# CONTROL_MODULE register map
Vendor: Texas Instruments
Registers are 32-bit, access per field, no defined reset value unless marked. A register's access mark holds for its fields unless they carry their own. Offsets are as the file gives them; [hi:lo] are bit positions; lines under a group give offsets from that group; {n}, {i} and the like mark numbered series.

## CONTROL_MODULE (part 2 of 5)
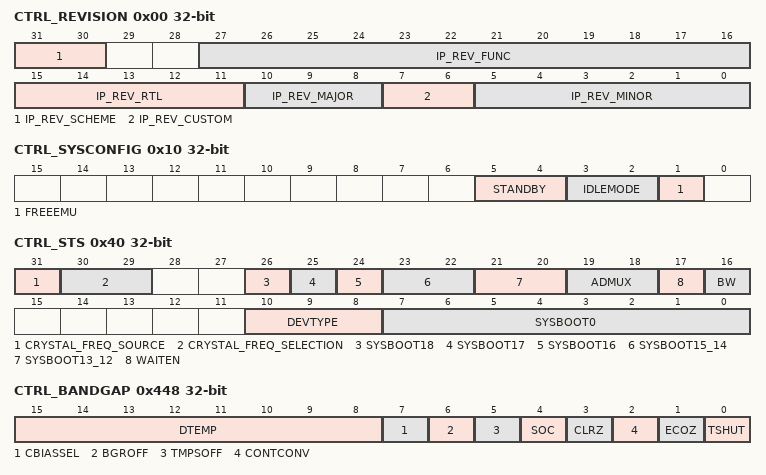
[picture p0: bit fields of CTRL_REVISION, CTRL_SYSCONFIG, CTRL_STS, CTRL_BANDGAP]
0x00 CTRL_REVISION ro
  [31:30] IP_REV_SCHEME — Scheme value
  [27:16] IP_REV_FUNC — Function value
  [15:11] IP_REV_RTL — RTL Version value
  [10:8] IP_REV_MAJOR — Major Revision value
  [7:6] IP_REV_CUSTOM — Custom Version value
  [5:0] IP_REV_MINOR — Minor Revision value
0x04 CTRL_HWINFO ro
  [31:0] IP_HWINFO — IP Module dependent
0x10 CTRL_SYSCONFIG
  [5:4] STANDBY ro — Configure local initiator state management [[br]]00 : Force Standby[[br]] [[br]]01 : No Standby Mode[[br]] [[br]]10 : Smart Standby[[br]] [[br]]11 : Smart Standby wakeup capable[[br]]Reserved in Control Module since it has no local initiator.
  [3:2] IDLEMODE rw — Configure local target state management [[br]]00 : Force Idle[[br]] [[br]]01 : No Idle[[br]] [[br]]10 : Smart Idle[[br]] [[br]]11 : Smart Idle wakeup capable
  [1] FREEEMU ro — Sensitivity to Emulation suspend input. [[br]]0 : Module is sensitive to EMU suspend[[br]] [[br]]1 : Module not sensitive to EMU suspend
0x40 CTRL_STS
  [31] CRYSTAL_FREQ_SOURCE ro — [[br]]0: Use SYSBOOT15_14 (bits 23 to 22) [[br]]1: Use crystal_freq_selection (bits 30 to 29)
  [30:29] CRYSTAL_FREQ_SELECTION ro — This register bitfield is valid only when crystal_freq_source (bit 31) is 1. [[br]]00: selects 19.2MHz[[br]] [[br]]01: selects 24MHz[[br]] [[br]]10: selects 25MHz[[br]] [[br]]11: selects 26MHz
  [26] SYSBOOT18 rw — Reserved for future
  [25] SYSBOOT17 rw — Used by Control Module to determine whether CLKOUT1 pin is selected as default mux mode on device pin xdma_event_intr0. [[br]]1: CLKOUT1 is selected as default mux mode[[br]] [[br]]0: Pinmux Mode0 function is selected as the default mux mode
  [24] SYSBOOT16 rw — Used by boot ROM [[br]]0: QSPI Mux mode 0 or gpmc wait0 Mux mode 0[[br]] [[br]]1: QSPI Mux mode 1 or gpmc wait0 Mux mode 1
  [23:22] SYSBOOT15_14 rw — Used to select crystal clock frequency. [[br]]This register bitfield is valid only when crystal_freq_source (bit 31) is 0. [[br]]00: Selects 19.2MHz[[br]] [[br]]01: Selects 24MHz[[br]] [[br]]10: Selects 25MHz[[br]] [[br]]11: Selects 26MHz
  [21:20] SYSBOOT13_12 rw — Reserved for future use
  [19:18] ADMUX rw — GPMC CS0 Default Address Muxing [[br]]00 : No Addr/Data Muxing[[br]] [[br]]01 : Addr/Addr/Data Muxing[[br]] [[br]]10 : Addr/Data Muxing[[br]] [[br]]11 : Reserved
  [17] WAITEN rw — GPMC CS0 Default Wait Enable [[br]]0 : Ignore WAIT input[[br]] [[br]]1 : Use WAIT input
  [16] BW rw — GPMC CS0 Default Bus Width [[br]]0: 8 bit data bus[[br]]1: 16 bit data bus
  [10:8] DEVTYPE ro — [[br]]000: Reserved[[br]] [[br]]001: Reserved[[br]] [[br]]010: Reserved[[br]] [[br]]011: General Purpose (GP) Device[[br]] [[br]]111: Reserved
  [7:0] SYSBOOT0 rw — SYSBOOT0 (bits 7 to 6): Used by Boot ROM for selecting MII/RMII/RGMII modes(1)[[br]]00b - MII[[br]]01b - RMII[[br]]10b - RGMII with internal delay[[br]]11b - RGMII without internal delay[[br]]SYSBOOT0(bits 5 to 0): ROM Boot Selection
0x1E0 CTRL_MPU_L2
  [16] PIUSEL2SRAM rw — Enables MPUSS L2 Cache as SRAM[[br]] [[br]]0 - Select L2 cache operation[[br]] [[br]]1 - Configure L2 cache as L3 OCMC RAM
0x428 CTRL_CORE_SLDO
  [25:16] VSET rw — Trims VDDAR
0x42C CTRL_MPU_SLDO
  [25:16] VSET rw — Trims VDDAR
0x444 CTRL_CLK32KDIVRATIO
  [0] CLKDIVOPP50_EN rw — [[br]]0 : OPP100 operation use ratio for 24MHz to 32KHz division [[br]]1 : OPP50 operation use ratio for 12MHz to 32KHz division
0x448 CTRL_BANDGAP
  [15:8] DTEMP ro — temperature data from ADC
  [7] CBIASSEL rw — high uses resister divider as reference rather than bandgap. [[br]]Wait 150us after BGROFF=0 then pull it low
  [6] BGROFF rw — high turns off bandgap (OFF mode)
  [5] TMPSOFF rw — high turns off temperature sensor
  [4] SOC rw — high transition starts new ADC conversion cycle
  [3] CLRZ rw — low resets the digital outputs
  [2] CONTCONV rw — high is continuous conversion mode low is single conversion mode
  [1] ECOZ ro — when low DTEMP is valid
  [0] TSHUT ro — goes high during thermal shutdown event (147C)
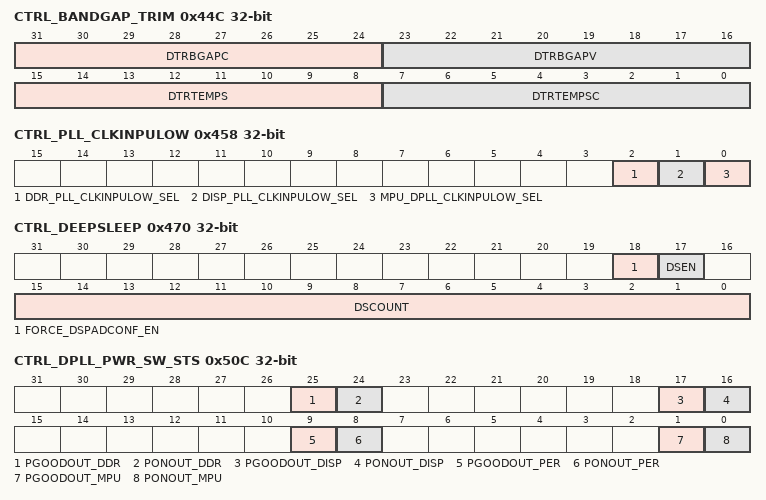
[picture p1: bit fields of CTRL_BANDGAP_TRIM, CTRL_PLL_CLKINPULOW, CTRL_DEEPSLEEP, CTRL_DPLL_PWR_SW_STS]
0x44C CTRL_BANDGAP_TRIM rw
  [31:24] DTRBGAPC — trim the output voltage of bandgap
  [23:16] DTRBGAPV — trim the output voltage of bandgap
  [15:8] DTRTEMPS — trim the temperature sensor
  [7:0] DTRTEMPSC — trim the temperature sensor
0x458 CTRL_PLL_CLKINPULOW
  [2] DDR_PLL_CLKINPULOW_SEL rw — [[br]]0 : Select CORE_CLKOUT_M6 clock as CLKINPULOW [[br]]1 : Select PER_CLKOUT_M2 clock as CLKINPULOW
  [1] DISP_PLL_CLKINPULOW_SEL rw — [[br]]0 : Select CORE_CLKOUT_M6 clock as CLKINPULOW [[br]]1 : Select PER_CLKOUT_M2 clock as CLKINPULOW
  [0] MPU_DPLL_CLKINPULOW_SEL rw — [[br]]0 : Select CORE_CLKOUT_M6 clock as CLKINPULOW [[br]]1 : Select PER_CLKOUT_M2 clock as CLKINPULOW
0x468 CTRL_MOSC
  [0] RESSELECT rw — [[br]]0 : When reselect is low an internal 1megohm resistor is connected between padxi and padxo for oscillator bias. [[br]]1 : When resselect is asserted (high) the internal resistor is disconnected. [[br]]For oscillation with a crystal while resselect is high an external resistor must be connected between padxi and padxo to provide bias.
0x470 CTRL_DEEPSLEEP
  [18] FORCE_DSPADCONF_EN rw — Forces the DSPADCONF by overriding control from PRCM
  [17] DSEN rw — Deep Sleep Enable When this bit is set the master oscillator clock is gated
  [15:0] DSCOUNT rw — Programmable count of how many OSC clocks needs to be seen before exiting deep sleep mode
0x50C CTRL_DPLL_PWR_SW_STS ro
  [25] PGOODOUT_DDR — PGOODOUT signals from DDR DPLL
  [24] PONOUT_DDR — PONOUT signal from DDR DPLL
  [17] PGOODOUT_DISP — PGOODOUT signal from DISP DPLL
  [16] PONOUT_DISP — PONOUT signal from DISP DPLL
  [9] PGOODOUT_PER — PGOODOUT signal from PER DPLL
  [8] PONOUT_PER — PONOUT signal from PER DPLL
  [1] PGOODOUT_MPU — PGOODOUT signal from MPU DPLL
  [0] PONOUT_MPU — PONOUT signal from MPU DPLL
0x534 CTRL_DISPLAY_PLL_SEL
  [0] SELECT rw — [[br]]0 : PRCM controls display PLL [[br]]1 : DISPPLL_* controls display PLL
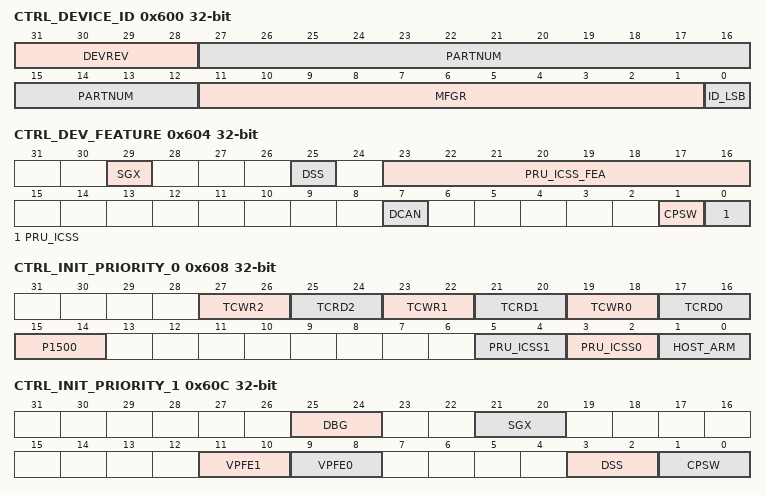
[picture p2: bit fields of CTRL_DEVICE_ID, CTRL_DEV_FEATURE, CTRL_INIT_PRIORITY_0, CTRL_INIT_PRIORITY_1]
0x600 CTRL_DEVICE_ID ro
  [31:28] DEVREV — Device revision
  [27:12] PARTNUM — Device part number (unique JTAG ID)
  [11:1] MFGR — Manufacturer's JTAG ID
  [0] ID_LSB — Reserved - always 1
0x604 CTRL_DEV_FEATURE ro
  [29] SGX — When set indicates 3D Graphics (SGX) is Enabled
  [25] DSS — When set indicates DSS is Enabled
  [23:16] PRU_ICSS_FEA — Individual bits being enabled indicate certain PRU-ICSS Features are enabled. [[br]]Please refer to PRU-ICSS documentation for details.
  [7] DCAN — When set indicates DCAN is enabled (DCAN0 and DCAN1)
  [1] CPSW — When set indicates that CPSW is enabled
  [0] PRU_ICSS — When set indicates PRU-ICSS module is enabled
0x608 CTRL_INIT_PRIORITY_0
  [27:26] TCWR2 rw — TPTC 2 Write Port initiator priority
  [25:24] TCRD2 rw — TPTC 2 Read Port initiator priority
  [23:22] TCWR1 rw — TPTC 1 Write Port initiator priority
  [21:20] TCRD1 rw — TPTC 1 Read Port initiator priority
  [19:18] TCWR0 rw — TPTC 1 Write Port initiator priority
  [17:16] TCRD0 rw — TPTC 1 Read Port initiator priority
  [15:14] P1500 rw — P1500 Port Initiator priority
  [5:4] PRU_ICSS1 rw — PRU-ICSS1 initiator priority
  [3:2] PRU_ICSS0 rw — Reserved
  [1:0] HOST_ARM rw — Host ARM MPU initiator priority
0x60C CTRL_INIT_PRIORITY_1
  [25:24] DBG rw — Debug Subsystem initiator priority
  [21:20] SGX rw — SGX initiator priority
  [11:10] VPFE1 rw — VPFE1 initiator priority
  [9:8] VPFE0 rw — VPFE0 initiator priority
  [3:2] DSS rw — DSS DMA port initiator priority
  [1:0] CPSW rw — CPSW initiator priority
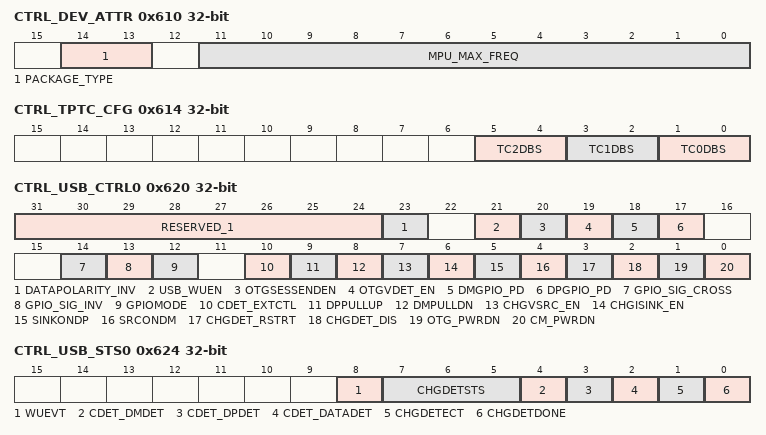
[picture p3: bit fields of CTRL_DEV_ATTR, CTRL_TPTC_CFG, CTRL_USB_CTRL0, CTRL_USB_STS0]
0x610 CTRL_DEV_ATTR ro
  [14:13] PACKAGE_TYPE — 00b - ZDN[[br]] 01b - Reserved[[br]] 10b - Reserved[[br]] 11b - Reserved
  [11:0] MPU_MAX_FREQ — 0xFFA 600MHz ARM MPU Maximum[[br]] 0xFC2 1GHz ARM MPU Maximum
0x614 CTRL_TPTC_CFG
  [5:4] TC2DBS rw — TC2 Default Burst Size [[br]]00 = 16 byte[[br]] [[br]]01 = 32 byte[[br]] [[br]]10 = 64 byte[[br]] [[br]]11 = 128 byte
  [3:2] TC1DBS rw — TC1 Default Burst Size
  [1:0] TC0DBS rw — TC0 Default Burst Size
0x620 CTRL_USB_CTRL0
  [31:24] RESERVED_1 rw — Reserved. [[br]]Any writes to this register must keep these bits set to 0x3C.
  [23] DATAPOLARITY_INV rw — Data Polarity Invert: [[br]]0: DP/DM (normal polarity matching port definition) [[br]]1: DM/DP (inverted polarity of port definition)
  [21] USB_WUEN rw — USB Wakeup Enable
  [20] OTGSESSENDEN rw — Session End Detect Enable [[br]]0 : Disable Session End Comparator[[br]]1 : Turns on Session End Comparator
  [19] OTGVDET_EN rw — VBUS Detect Enable [[br]]0 : Disable VBUS Detect Enable[[br]]1 : Turns on all comparators except Session End comparator
  [18] DMGPIO_PD rw — Pull-down on DM in GPIO Mode [[br]]0 : Enables pull-down[[br]]1 : Disables pull-down
  [17] DPGPIO_PD rw — Pull-down on DP in GPIO Mode [[br]]0 : Enables pull-down[[br]]1 : Disables pull-down
  [14] GPIO_SIG_CROSS rw — UART TX -> DM. [[br]]UART RX -> DP.
  [13] GPIO_SIG_INV rw — UART TX -> Invert -> DP. [[br]]UART RX -> Invert -> DM.
  [12] GPIOMODE rw — GPIO Mode [[br]]0 : USB Mode[[br]]1 : GPIO Mode (UART Mode)
  [10] CDET_EXTCTL rw — Bypass the charger detection state machine [[br]]0 : Charger detection on[[br]]1 : Charger detection is bypassed
  [9] DPPULLUP rw — Pull-up on DP line [[br]]0 : No effect[[br]]1 : Enable pull-up on DP line
  [8] DMPULLDN rw — Pull-down on DM line [[br]]0 : No effect[[br]]1 : Enable pull-down on DM line
  [7] CHGVSRC_EN rw — Enable VSRC on DP line (Host Charger case)
  [6] CHGISINK_EN rw — Enable ISINK on DM line (Host Charger case)
  [5] SINKONDP rw — Sink on DP [[br]]0 : Sink on DM[[br]]1 : Sink on DP
  [4] SRCONDM rw — Source on DM [[br]]0 : Source on DP[[br]]1 : Source on DM
  [3] CHGDET_RSTRT rw — Restart Charger Detect
  [2] CHGDET_DIS rw — Charger Detect Disable [[br]]0 : Enable[[br]]1 : Disable
  [1] OTG_PWRDN rw — Power down the USB OTG PHY [[br]]1 : PHY Powered down[[br]]0 : PHY in normal mode
  [0] CM_PWRDN rw — Power down the USB CM PHY [[br]]1 : PHY Powered down[[br]]0 : PHY in normal mode
0x624 CTRL_USB_STS0 ro
  [8] WUEVT — Wakeup Event
  [7:5] CHGDETSTS — Charge Detection Status [[br]]000: Wait State (When a D+WPU and D-15K are connected it enters into this state and will remain in this state unless it enters into other state)[[br]] [[br]]001: No Contact[[br]] [[br]]010: PS/2[[br]] [[br]]011: Unknown error[[br]] [[br]]100: Dedicated charger (valid if CE is HIGH)[[br]] [[br]]101: HOST charger (valid if CE is HIGH)[[br]] [[br]]110: PC[[br]] [[br]]111: Interrupt (if any of the pullup is enabled charger detect routine gets interrupted and will restart from the beginning if the same is disabled)
  [4] CDET_DMDET — DM Comparator Output
  [3] CDET_DPDET — DP Comparator Output
  [2] CDET_DATADET — Charger Comparator Output
  [1] CHGDETECT — Charger Detection Status [[br]]0 : Charger was not detected[[br]]1 : Charger was detected
  [0] CHGDETDONE — Charger Detection Protocol Done
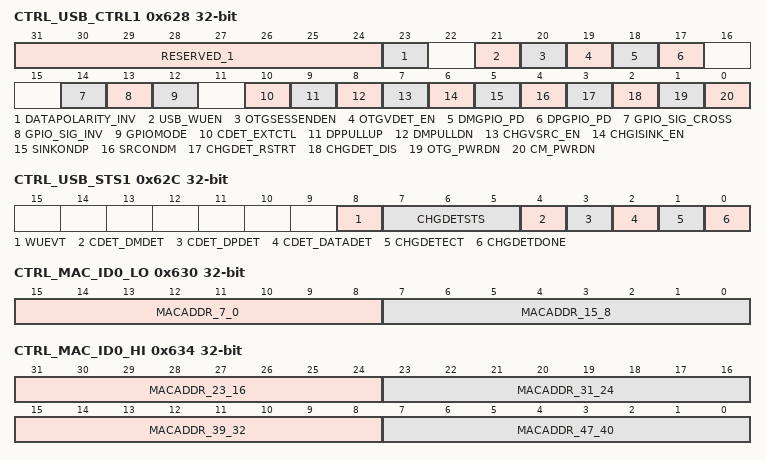
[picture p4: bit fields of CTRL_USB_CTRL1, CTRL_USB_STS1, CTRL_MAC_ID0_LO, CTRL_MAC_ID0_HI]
0x628 CTRL_USB_CTRL1
  [31:24] RESERVED_1 rw — Reserved. [[br]]Any writes to this register must keep these bits set to 0x3C.
  [23] DATAPOLARITY_INV rw — Data Polarity Invert: [[br]]0: DP/DM (normal polarity matching port definition) [[br]]1: DM/DP (inverted polarity of port definition)
  [21] USB_WUEN rw — USB Wakeup Enable
  [20] OTGSESSENDEN rw — Session End Detect Enable [[br]]0 : Disable Session End Comparator[[br]]1 : Turns on Session End Comparator
  [19] OTGVDET_EN rw — VBUS Detect Enable [[br]]0 : Disable VBUS Detect Enable[[br]]1 : Turns on all comparators except Session End comparator
  [18] DMGPIO_PD rw — Pull-down on DM in GPIO Mode [[br]]0 : Enables pull-down[[br]]1 : Disables pull-down
  [17] DPGPIO_PD rw — Pull-down on DP in GPIO Mode [[br]]0 : Enables pull-down[[br]]1 : Disables pull-down
  [14] GPIO_SIG_CROSS rw — UART TX -> DM. [[br]]UART RX -> DP.
  [13] GPIO_SIG_INV rw — UART TX -> INV -> DP. [[br]]UART RX -> INV -> DM.
  [12] GPIOMODE rw — GPIO Mode [[br]]0 : USB Mode[[br]]1 : GPIO Mode (UART)
  [10] CDET_EXTCTL rw — Bypass the charger detection state machine [[br]]0 : Charger detection on[[br]]1 : Charger detection is bypassed
  [9] DPPULLUP rw — Pull-up on DP line [[br]]0 : No effect[[br]]1 : Enable pull-up on DP line
  [8] DMPULLDN rw — Pull-down on DM line [[br]]0 : No effect[[br]]1 : Enable pull-down on DM line
  [7] CHGVSRC_EN rw — Enable VSRC on DP line (Host Charger case)
  [6] CHGISINK_EN rw — Enable ISINK on DM line (Host Charger case)
  [5] SINKONDP rw — Sink on DP [[br]]0 : Sink on DM[[br]]1 : Sink on DP
  [4] SRCONDM rw — Source on DM [[br]]0 : Source on DP[[br]]1 : Source on DM
  [3] CHGDET_RSTRT rw — Restart Charger Detect
  [2] CHGDET_DIS rw — Charger Detect Disable [[br]]0 : Enable[[br]]1 : Disable
  [1] OTG_PWRDN rw — Power down the USB OTG PHY [[br]]1 : PHY Powered down[[br]]0 : PHY in normal mode
  [0] CM_PWRDN rw — Power down the USB CM PHY [[br]]1 : PHY Powered down[[br]]0 : PHY in normal mode
0x62C CTRL_USB_STS1 ro
  [8] WUEVT — Wakeup Event
  [7:5] CHGDETSTS — Charge Detection Status [[br]]000: Wait State (When a D+WPU and D-15K are connected it enters into this state and will remain in this state unless it enters into other state)[[br]] [[br]]001: No Contact[[br]] [[br]]010: PS/2[[br]] [[br]]011: Unknown error[[br]] [[br]]100: Dedicated charger (valid if CE is HIGH)[[br]] [[br]]101: HOST charger (valid if CE is HIGH)[[br]] [[br]]110: PC[[br]] [[br]]111: Interrupt (if any of the pullup is enabled charger detect routine gets interrupted and will restart from the beginning if the same is disabled)
  [4] CDET_DMDET — DM Comparator Output
  [3] CDET_DPDET — DP Comparator Output
  [2] CDET_DATADET — Charger Comparator Output
  [1] CHGDETECT — Charger Detection Status [[br]]0 : Charger was no detected[[br]]1 : Charger was detected
  [0] CHGDETDONE — Charger Detection Protocol Done
0x630 CTRL_MAC_ID0_LO ro
  [15:8] MACADDR_7_0 — MAC0 Address - Byte 0. [[br]]Reset value is device-dependent.
  [7:0] MACADDR_15_8 — MAC0 Address - Byte 1. [[br]]Reset value is device-dependent.
0x634 CTRL_MAC_ID0_HI ro
  [31:24] MACADDR_23_16 — MAC0 Address - Byte 2. [[br]]Reset value is device-dependent.
  [23:16] MACADDR_31_24 — MAC0 Address - Byte 3. [[br]]Reset value is device-dependent.
  [15:8] MACADDR_39_32 — MAC0 Address - Byte 4. [[br]]Reset value is device-dependent.
  [7:0] MACADDR_47_40 — MAC0 Address - Byte 5. [[br]]Reset value is device-dependent.
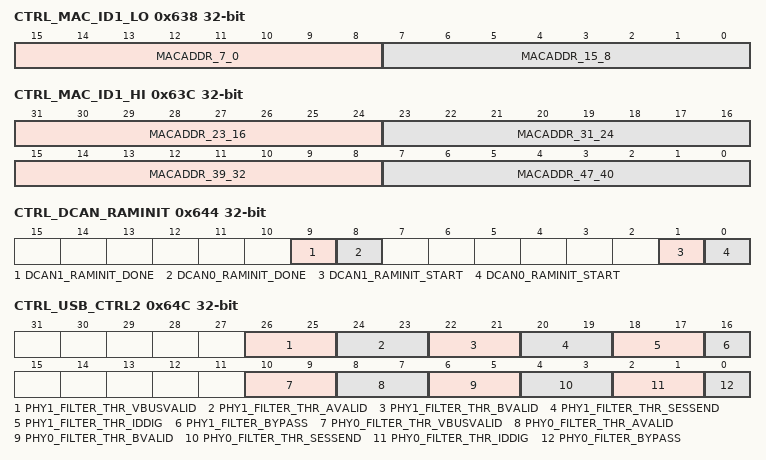
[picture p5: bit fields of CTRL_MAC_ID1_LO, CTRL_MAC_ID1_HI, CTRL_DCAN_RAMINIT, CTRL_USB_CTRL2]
0x638 CTRL_MAC_ID1_LO ro
  [15:8] MACADDR_7_0 — MAC1 Address - Byte 0. [[br]]Reset value is device-dependent.
  [7:0] MACADDR_15_8 — MAC1 Address - Byte 1. [[br]]Reset value is device-dependent.
0x63C CTRL_MAC_ID1_HI ro
  [31:24] MACADDR_23_16 — MAC1 Address - Byte 2. [[br]]Reset value is device-dependent.
  [23:16] MACADDR_31_24 — MAC1 Address - Byte 3. [[br]]Reset value is device-dependent.
  [15:8] MACADDR_39_32 — MAC1 Address - Byte 4. [[br]]Reset value is device-dependent.
  [7:0] MACADDR_47_40 — MAC1 Address - Byte 5. [[br]]Reset value is device-dependent.
0x644 CTRL_DCAN_RAMINIT
  [9] DCAN1_RAMINIT_DONE wo — [[br]]1: DCAN1 RAM Initialization complete [[br]]0: DCAN1 RAM Initialization NOT complete
  [8] DCAN0_RAMINIT_DONE wo — [[br]]1: DCAN0 RAM Initialization complete [[br]]0: DCAN0 RAM Initialization NOT complete
  [1] DCAN1_RAMINIT_START rw — A transition from 0 to 1 will start DCAN1 RAM initialization sequence.
  [0] DCAN0_RAMINIT_START rw — A transition from 0 to 1 will start DCAN1 RAM initialization sequence.
0x64C CTRL_USB_CTRL2
  [26:25] PHY1_FILTER_THR_VBUSVALID rw — PHY1_FILTER_THRESHOLD for VBUSVALID to fliter out oscillations from PHY1. [[br]]0 = 1us[[br]]1 = 100us[[br]]2 = 5ms[[br]]3 = 500ms
  [24:23] PHY1_FILTER_THR_AVALID rw — PHY1_FILTER_THRESHOLD for AVALID to fliter out oscillations from PHY1. [[br]]0 = 1us[[br]]1 = 100us[[br]]2 = 5ms[[br]]3 = 500ms
  [22:21] PHY1_FILTER_THR_BVALID rw — PHY1_FILTER_THRESHOLD for AVALID to fliter out oscillations from PHY1. [[br]]0 = 1us[[br]]1 = 100us[[br]]2 = 5ms[[br]]3 = 500ms
  [20:19] PHY1_FILTER_THR_SESSEND rw — PHY1_FILTER_THRESHOLD for AVALID to fliter out oscillations from PHY1. [[br]]0 = 1us[[br]]1 = 100us[[br]]2 = 5ms[[br]]3 = 500ms
  [18:17] PHY1_FILTER_THR_IDDIG rw — PHY1_FILTER_THRESHOLD for AVALID to fliter out oscillations from PHY1. [[br]]0 = 1us[[br]]1 = 100us[[br]]2 = 5ms[[br]]3 = 500ms
  [16] PHY1_FILTER_BYPASS rw — [[br]]0 = Filter to filter oscillations from PHY1 is not bypassed[[br]] [[br]]1 = Filter is bypassed
  [10:9] PHY0_FILTER_THR_VBUSVALID rw — PHY0_FILTER_THRESHOLD for VBUSVALID to fliter out oscillations from PHY0. [[br]]0 = 1us[[br]]1 = 100us[[br]]2 = 5ms[[br]]3 = 500ms
  [8:7] PHY0_FILTER_THR_AVALID rw — PHY0_FILTER_THRESHOLD for AVALID to fliter out oscillations from PHY0. [[br]]0 = 1us[[br]]1 = 100us[[br]]2 = 5ms[[br]]3 = 500ms
  [6:5] PHY0_FILTER_THR_BVALID rw — PHY0_FILTER_THRESHOLD for AVALID to fliter out oscillations from PHY0. [[br]]0 = 1us[[br]]1 = 100us[[br]]2 = 5ms[[br]]3 = 500ms
  [4:3] PHY0_FILTER_THR_SESSEND rw — PHY0_FILTER_THRESHOLD for AVALID to fliter out oscillations from PHY0. [[br]]0 = 1us[[br]]1 = 100us[[br]]2 = 5ms[[br]]3 = 500ms
  [2:1] PHY0_FILTER_THR_IDDIG rw — PHY0_FILTER_THRESHOLD for AVALID to fliter out oscillations from PHY0. [[br]]0 = 1us[[br]]1 = 100us[[br]]2 = 5ms[[br]]3 = 500ms
  [0] PHY0_FILTER_BYPASS rw — [[br]]0 - Filter to filter oscillations from PHY0 is not bypassed[[br]] [[br]]1 - Filter is bypassed
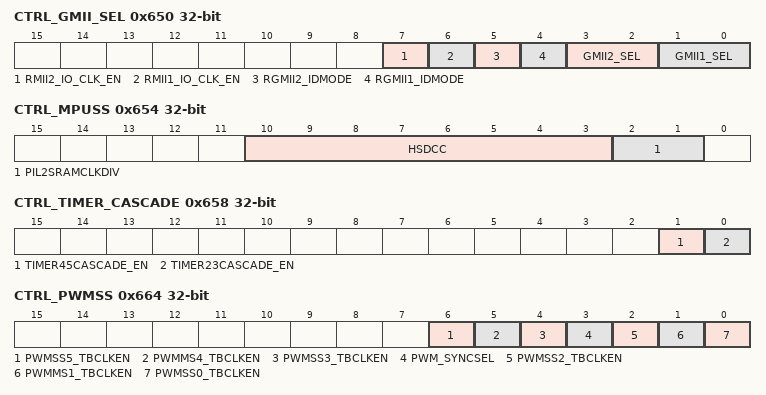
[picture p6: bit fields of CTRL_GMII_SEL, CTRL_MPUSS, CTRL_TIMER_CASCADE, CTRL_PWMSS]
0x650 CTRL_GMII_SEL
  [7] RMII2_IO_CLK_EN rw — [[br]]1 : Enable RMII clock to be sourced from chip pin [[br]]0 : Enable RMII clock to be sourced from PLL
  [6] RMII1_IO_CLK_EN rw — [[br]]1 : Enable RMII clock to be sourced from chip pin [[br]]0 : Enable RMII clock to be sourced from PLL
  [5] RGMII2_IDMODE rw — RGMII2 Internal Delay Mode [[br]]0 : Internal Delay[[br]]1 : No Internal Delay
  [4] RGMII1_IDMODE rw — RGMII1 Internal Delay Mode [[br]]0 : Internal Delay[[br]]1 : No Internal Delay
  [3:2] GMII2_SEL rw — [[br]]00 : Port2 GMII/MII Mode [[br]]01 : Port2 RMII Mode[[br]]10 : Port2 RGMII Mode[[br]]11 : Not Used
  [1:0] GMII1_SEL rw — [[br]]00 : Port1 GMII/MII Mode [[br]]01 : Port1 RMII Mode[[br]]10 : Port1 RGMII Mode[[br]]11 : Not Used
0x654 CTRL_MPUSS
  [10:3] HSDCC rw — (Bit 3): CLK[[br]] (Bits 6 to 4): ADDR[[br]] (Bits 10 to 7): DATA
  [2:1] PIL2SRAMCLKDIV rw — [[br]]00 : MPU_CLK/2 [[br]]01 : MPU_CLK/3[[br]]10 : MPU_CLK/4[[br]]11 : MPU_CLK/6
0x658 CTRL_TIMER_CASCADE
  [1] TIMER45CASCADE_EN rw — [[br]]1 - Enables cascading of timer4 and timer5[[br]]
  [0] TIMER23CASCADE_EN rw — [[br]]1 - Enables cascading of timer2 and timer3[[br]]
0x664 CTRL_PWMSS
  [6] PWMSS5_TBCLKEN rw — Timebase clock enable for PWMSS5
  [5] PWMMS4_TBCLKEN rw — Timebase clock enable for PWMSS4
  [4] PWMSS3_TBCLKEN rw — Timebase clock enable for PWMSS3
  [3] PWM_SYNCSEL rw — [[br]]0: PWM3 sync is from PWM2 (daisy chained)[[br]] [[br]]1: PWM3 sync is from PIN (eHRPWM3)
  [2] PWMSS2_TBCLKEN rw — Timebase clock enable for PWMSS2
  [1] PWMMS1_TBCLKEN rw — Timebase clock enable for PWMSS1
  [0] PWMSS0_TBCLKEN rw — Timebase clock enable for PWMSS0
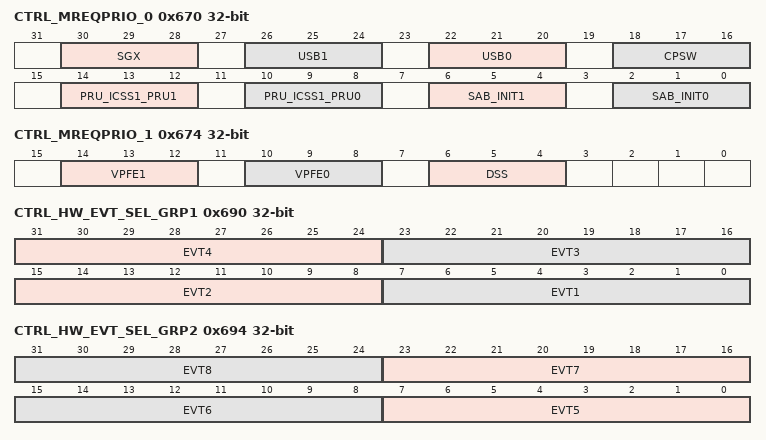
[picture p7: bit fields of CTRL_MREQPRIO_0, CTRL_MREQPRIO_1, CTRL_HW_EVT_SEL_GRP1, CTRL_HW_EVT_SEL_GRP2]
0x670 CTRL_MREQPRIO_0
  [30:28] SGX rw — MReqPriority for SGX Initiator OCP Interface
  [26:24] USB1 rw — Reserved : AXI does not support
  [22:20] USB0 rw — Reserved : AXI does not support
  [18:16] CPSW rw — MReqPriority for CPSW Initiator OCP Interface
  [14:12] PRU_ICSS1_PRU1 rw — MReqPriority for PRU-ICSS1 PRU1Initiator OCP Interface
  [10:8] PRU_ICSS1_PRU0 rw — MReqPriority for PRU-ICSS1 PRU0 Initiator OCP Interface
  [6:4] SAB_INIT1 rw — MReqPriority for MPUSS Initiator 1 OCP Interface
  [2:0] SAB_INIT0 rw — This is reserved and not used since the MPUSS IP itself supports this signal.
0x674 CTRL_MREQPRIO_1
  [14:12] VPFE1 rw — MReqPriority for VPFE1 OCP Interface
  [10:8] VPFE0 rw — MReqPriority for VPFE0 OCP Interface
  [6:4] DSS rw — MReqPriority for DSS OCP Interface
0x690 CTRL_HW_EVT_SEL_GRP1 rw
  [31:24] EVT4 — Select 4th trace event from group 1
  [23:16] EVT3 — Select 3rd trace event from group 1
  [15:8] EVT2 — Select 2nd trace event from group 1
  [7:0] EVT1 — Select 1st trace event from group 1
0x694 CTRL_HW_EVT_SEL_GRP2 rw
  [8n-33:8n-40] EVT{n} (n=5..8) — Select {n}th trace event from group 2
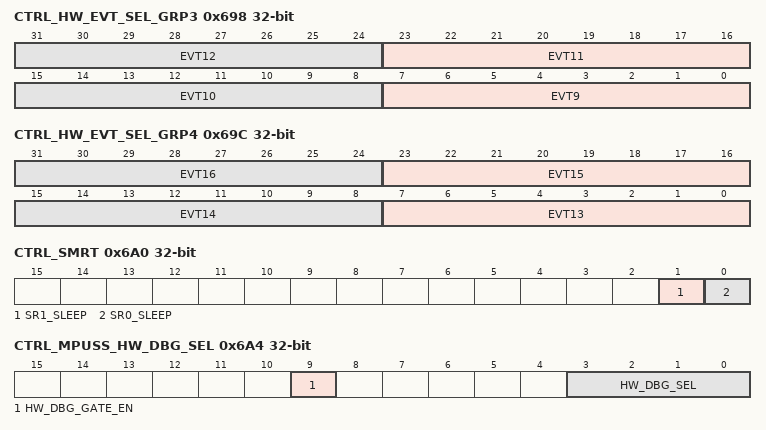
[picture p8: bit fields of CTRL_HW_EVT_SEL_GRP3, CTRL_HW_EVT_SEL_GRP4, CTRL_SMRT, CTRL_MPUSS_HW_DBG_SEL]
0x698 CTRL_HW_EVT_SEL_GRP3 rw
  [8n-65:8n-72] EVT{n} (n=9..12) — Select {n}th trace event from group 3
0x69C CTRL_HW_EVT_SEL_GRP4 rw
  [8n-97:8n-104] EVT{n} (n=13..16) — Select {n}th trace event from group 4
0x6A0 CTRL_SMRT
  [1] SR1_SLEEP rw — [[br]]0 = disable sensor (SRSLEEP on sensor driven to 1) [[br]]1= enable sensor (SRSLEEP on sensor driven to 0).
  [0] SR0_SLEEP rw — [[br]]0 = disable sensor (SRSLEEP on sensor driven to 1) [[br]]1 = enable sensor (SRSLEEP on sensor driven to 0).
0x6A4 CTRL_MPUSS_HW_DBG_SEL
  [9] HW_DBG_GATE_EN rw — To save power input to MPUSS_HW_DBG_INFO is gated off to all zeros when HW_DBG_GATE_EN bit is low. [[br]]0 : Debug info gated off[[br]]1 : Debug info not gated off
  [3:0] HW_DBG_SEL rw — Selects which Group of signals are sent out to the MODENA_HW_DBG_INFO register. [[br]]Please see MPU functional spec for more details. [[br]]0000: Group 0[[br]] [[br]]0001: Group 1[[br]] [[br]]0010: Group 2[[br]] [[br]]0011: Group 3[[br]] [[br]]0100: Group 4[[br]] [[br]]0101: Group 5[[br]] [[br]]0110: Group 6[[br]] [[br]]0111: Group 7[[br]] 1xxx: Reserved
0x6A8 CTRL_MPUSS_HW_DBG_INFO ro
  [31:0] HW_DBG_INFO — Hardware Debug Info from MPUSS.
0x770 CTRL_VDD_MPU_OPP_050 ro
  [23:0] NTARGET — Ntarget value for MPU Voltage domain OPP50. [[br]]Reset value is device-dependent.
0x774 CTRL_VDD_MPU_OPP_100 ro
  [23:0] NTARGET — Ntarget value for MPU Voltage domain OPP100. [[br]]Reset value is device-dependent.
0x778 CTRL_VDD_MPU_OPP_120 ro
  [23:0] NTARGET — Ntarget value for MPU Voltage domain OPP120. [[br]]Reset value is device-dependent.
0x77C CTRL_VDD_MPU_OPP_TURBO ro
  [23:0] NTARGET — Ntarget value for MPU Voltage domain OPPTURBO. [[br]]Reset value is device-dependent.
0x780 CTRL_VDD_MPU_OPP_NITRO ro
  [23:0] NTARGET — Ntarget value for MPU Voltage domain OPPNITRO. [[br]]Reset value is device-dependent.
0x7B8 CTRL_VDD_CORE_OPP_050 ro
  [23:0] NTARGET — Ntarget value for CORE Voltage domain OPP50. [[br]]Reset value is device-dependent.
0x7BC CTRL_VDD_CORE_OPP_100 ro
  [23:0] NTARGET — Ntarget value for CORE Voltage domain OPP100. [[br]]Reset value is device-dependent.
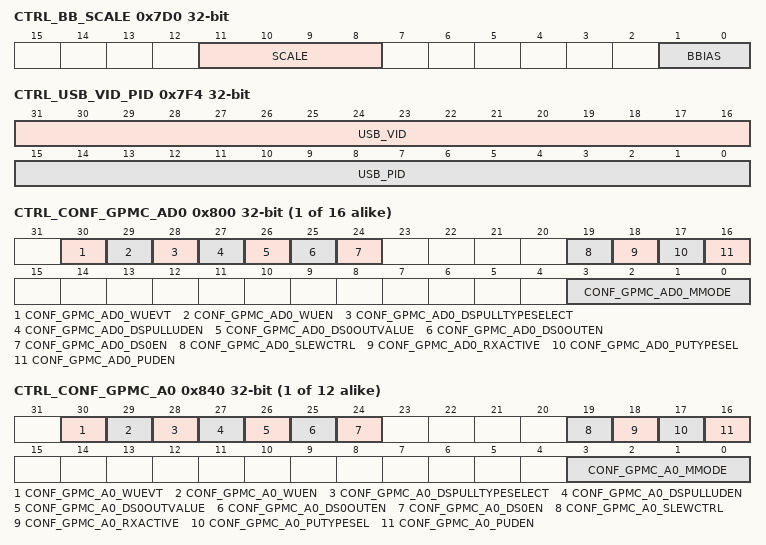
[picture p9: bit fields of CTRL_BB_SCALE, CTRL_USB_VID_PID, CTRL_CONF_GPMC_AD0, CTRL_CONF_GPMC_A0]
0x7D0 CTRL_BB_SCALE ro
  [11:8] SCALE — Dynamic Core Voltage Scaling For class 0 smart reflex.
  [1:0] BBIAS — BBIAS value from Efuse
0x7F4 CTRL_USB_VID_PID ro
  [31:16] USB_VID — USB Vendor ID
  [15:0] USB_PID — USB Product ID
{0x800+4i} CTRL_CONF_GPMC_AD{i} (i=0..15)
  [30] CONF_GPMC_AD{i}_WUEVT ro — Wakeup Event [[br]]0 = No event [[br]]1 = Event occurred
  [29] CONF_GPMC_AD{i}_WUEN rw — Wakeup enable [[br]]0 = disable [[br]]1 = enable
  [28] CONF_GPMC_AD{i}_DSPULLTYPESELECT rw — DS0 mode Pull-Up/Down selection [[br]]0 = Offmode Pull-Down selected [[br]]1 = Offmode Pull-Up selected
  [27] CONF_GPMC_AD{i}_DSPULLUDEN rw — DS0 mode Pull-Up/Down enable. [[br]]This is an active low signal. [[br]]1 = Pullup / Pulldown disabled [[br]]0 = Pullup / Pulldown enabled
  [26] CONF_GPMC_AD{i}_DS0OUTVALUE rw — DS0 mode output value [[br]]0 = Set value at 0 [[br]]1 = Set value at 1
  [25] CONF_GPMC_AD{i}_DS0OUTEN rw — DS0 mode output enable This is an active low signal [[br]]0 = Output Enable [[br]]1 = Output Disable
  [24] CONF_GPMC_AD{i}_DS0EN rw — DS0 mode override control [[br]]0: IO state keeps its previous state when DS0 mode is active [[br]]1: IO state is forced to OFF mode value when DS0 mode is active
  [19] CONF_GPMC_AD{i}_SLEWCTRL rw — Select between Faster or Slower Slew rate [[br]]0 = fast [[br]]1 = slow
  [18] CONF_GPMC_AD{i}_RXACTIVE rw — Input Enable Value for the PAD [[br]]0 = receiver disabled [[br]]1 = receiver enabled
  [17] CONF_GPMC_AD{i}_PUTYPESEL rw — Pad Pullup / Pulldown Type Selection [[br]]0 = Pulldown selected [[br]]1 = Pullup selected
  [16] CONF_GPMC_AD{i}_PUDEN rw — Pad Pullup / Pulldown Enable. [[br]]This is an active low signal [[br]]1 = Pullup / Pulldown disabled [[br]]0 = Pullup / Pulldown enabled
  [3:0] CONF_GPMC_AD{i}_MMODE rw — Pad Functional Signal Mux Select
{0x840+4i} CTRL_CONF_GPMC_A{i} (i=0..11)
  [30] CONF_GPMC_A{i}_WUEVT ro — Wakeup Event [[br]]0 = No event [[br]]1 = Event occurred
  [29] CONF_GPMC_A{i}_WUEN rw — Wakeup enable [[br]]0 = disable [[br]]1 = enable
  [28] CONF_GPMC_A{i}_DSPULLTYPESELECT rw — DS0 mode Pull-Up/Down selection [[br]]0 = Offmode Pull-Down selected [[br]]1 = Offmode Pull-Up selected
  [27] CONF_GPMC_A{i}_DSPULLUDEN rw — DS0 mode Pull-Up/Down enable. [[br]]This is an active low signal. [[br]]1 = Pullup / Pulldown disabled [[br]]0 = Pullup / Pulldown enabled
  [26] CONF_GPMC_A{i}_DS0OUTVALUE rw — DS0 mode output value [[br]]0 = Set value at 0 [[br]]1 = Set value at 1
  [25] CONF_GPMC_A{i}_DS0OUTEN rw — DS0 mode output enable This is an active low signal [[br]]0 = Output Enable [[br]]1 = Output Disable
  [24] CONF_GPMC_A{i}_DS0EN rw — DS0 mode override control [[br]]0: IO state keeps its previous state when DS0 mode is active [[br]]1: IO state is forced to OFF mode value when DS0 mode is active
  [19] CONF_GPMC_A{i}_SLEWCTRL rw — Select between Faster or Slower Slew rate [[br]]0 = fast [[br]]1 = slow
  [18] CONF_GPMC_A{i}_RXACTIVE rw — Input Enable Value for the PAD [[br]]0 = receiver disabled [[br]]1 = receiver enabled
  [17] CONF_GPMC_A{i}_PUTYPESEL rw — Pad Pullup / Pulldown Type Selection [[br]]0 = Pulldown selected [[br]]1 = Pullup selected
  [16] CONF_GPMC_A{i}_PUDEN rw — Pad Pullup / Pulldown Enable. [[br]]This is an active low signal [[br]]1 = Pullup / Pulldown disabled [[br]]0 = Pullup / Pulldown enabled
  [3:0] CONF_GPMC_A{i}_MMODE rw — Pad Functional Signal Mux Select
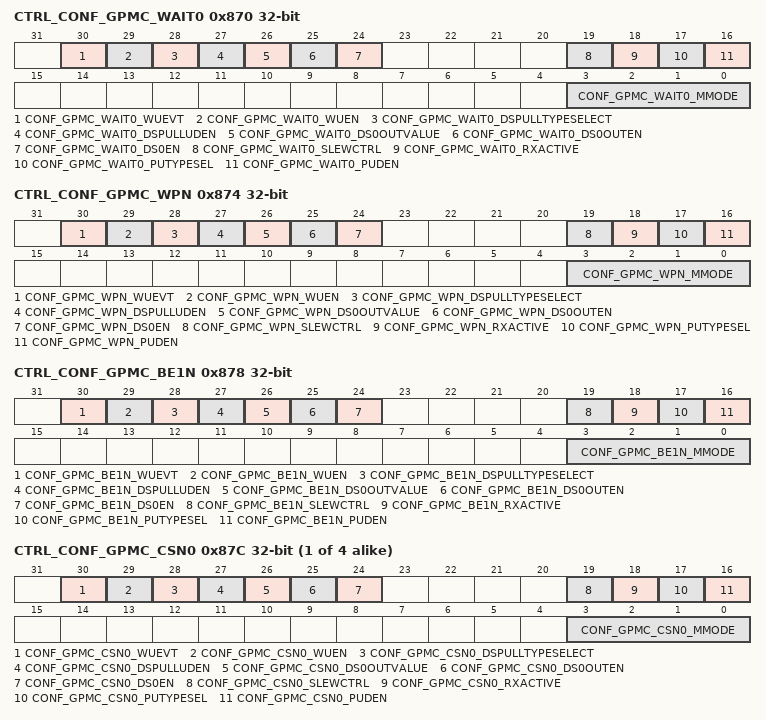
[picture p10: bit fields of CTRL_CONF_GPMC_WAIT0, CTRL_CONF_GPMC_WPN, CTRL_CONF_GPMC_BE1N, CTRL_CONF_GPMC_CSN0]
0x870 CTRL_CONF_GPMC_WAIT0
  [30] CONF_GPMC_WAIT0_WUEVT ro — Wakeup Event [[br]]0 = No event [[br]]1 = Event occurred
  [29] CONF_GPMC_WAIT0_WUEN rw — Wakeup enable [[br]]0 = disable [[br]]1 = enable
  [28] CONF_GPMC_WAIT0_DSPULLTYPESELECT rw — DS0 mode Pull-Up/Down selection [[br]]0 = Offmode Pull-Down selected [[br]]1 = Offmode Pull-Up selected
  [27] CONF_GPMC_WAIT0_DSPULLUDEN rw — DS0 mode Pull-Up/Down enable. [[br]]This is an active low signal. [[br]]1 = Pullup / Pulldown disabled [[br]]0 = Pullup / Pulldown enabled
  [26] CONF_GPMC_WAIT0_DS0OUTVALUE rw — DS0 mode output value [[br]]0 = Set value at 0 [[br]]1 = Set value at 1
  [25] CONF_GPMC_WAIT0_DS0OUTEN rw — DS0 mode output enable This is an active low signal [[br]]0 = Output Enable [[br]]1 = Output Disable
  [24] CONF_GPMC_WAIT0_DS0EN rw — DS0 mode override control [[br]]0: IO state keeps its previous state when DS0 mode is active [[br]]1: IO state is forced to OFF mode value when DS0 mode is active
  [19] CONF_GPMC_WAIT0_SLEWCTRL rw — Select between Faster or Slower Slew rate [[br]]0 = fast [[br]]1 = slow
  [18] CONF_GPMC_WAIT0_RXACTIVE rw — Input Enable Value for the PAD [[br]]0 = receiver disabled [[br]]1 = receiver enabled
  [17] CONF_GPMC_WAIT0_PUTYPESEL rw — Pad Pullup / Pulldown Type Selection [[br]]0 = Pulldown selected [[br]]1 = Pullup selected
  [16] CONF_GPMC_WAIT0_PUDEN rw — Pad Pullup / Pulldown Enable. [[br]]This is an active low signal [[br]]1 = Pullup / Pulldown disabled [[br]]0 = Pullup / Pulldown enabled
  [3:0] CONF_GPMC_WAIT0_MMODE rw — Pad Functional Signal Mux Select
0x874 CTRL_CONF_GPMC_WPN
  [30] CONF_GPMC_WPN_WUEVT ro — Wakeup Event [[br]]0 = No event [[br]]1 = Event occurred
  [29] CONF_GPMC_WPN_WUEN rw — Wakeup enable [[br]]0 = disable [[br]]1 = enable
  [28] CONF_GPMC_WPN_DSPULLTYPESELECT rw — DS0 mode Pull-Up/Down selection [[br]]0 = Offmode Pull-Down selected [[br]]1 = Offmode Pull-Up selected
  [27] CONF_GPMC_WPN_DSPULLUDEN rw — DS0 mode Pull-Up/Down enable. [[br]]This is an active low signal. [[br]]1 = Pullup / Pulldown disabled [[br]]0 = Pullup / Pulldown enabled
  [26] CONF_GPMC_WPN_DS0OUTVALUE rw — DS0 mode output value [[br]]0 = Set value at 0 [[br]]1 = Set value at 1
  [25] CONF_GPMC_WPN_DS0OUTEN rw — DS0 mode output enable This is an active low signal [[br]]0 = Output Enable [[br]]1 = Output Disable
  [24] CONF_GPMC_WPN_DS0EN rw — DS0 mode override control [[br]]0: IO state keeps its previous state when DS0 mode is active [[br]]1: IO state is forced to OFF mode value when DS0 mode is active
  [19] CONF_GPMC_WPN_SLEWCTRL rw — Select between Faster or Slower Slew rate [[br]]0 = fast [[br]]1 = slow
  [18] CONF_GPMC_WPN_RXACTIVE rw — Input Enable Value for the PAD [[br]]0 = receiver disabled [[br]]1 = receiver enabled
  [17] CONF_GPMC_WPN_PUTYPESEL rw — Pad Pullup / Pulldown Type Selection [[br]]0 = Pulldown selected [[br]]1 = Pullup selected
  [16] CONF_GPMC_WPN_PUDEN rw — Pad Pullup / Pulldown Enable. [[br]]This is an active low signal [[br]]1 = Pullup / Pulldown disabled [[br]]0 = Pullup / Pulldown enabled
  [3:0] CONF_GPMC_WPN_MMODE rw — Pad Functional Signal Mux Select
0x878 CTRL_CONF_GPMC_BE1N
  [30] CONF_GPMC_BE1N_WUEVT ro — Wakeup Event [[br]]0 = No event [[br]]1 = Event occurred
  [29] CONF_GPMC_BE1N_WUEN rw — Wakeup enable [[br]]0 = disable [[br]]1 = enable
  [28] CONF_GPMC_BE1N_DSPULLTYPESELECT rw — DS0 mode Pull-Up/Down selection [[br]]0 = Offmode Pull-Down selected [[br]]1 = Offmode Pull-Up selected
  [27] CONF_GPMC_BE1N_DSPULLUDEN rw — DS0 mode Pull-Up/Down enable. [[br]]This is an active low signal. [[br]]1 = Pullup / Pulldown disabled [[br]]0 = Pullup / Pulldown enabled
  [26] CONF_GPMC_BE1N_DS0OUTVALUE rw — DS0 mode output value [[br]]0 = Set value at 0 [[br]]1 = Set value at 1
  [25] CONF_GPMC_BE1N_DS0OUTEN rw — DS0 mode output enable This is an active low signal [[br]]0 = Output Enable [[br]]1 = Output Disable
  [24] CONF_GPMC_BE1N_DS0EN rw — DS0 mode override control [[br]]0: IO state keeps its previous state when DS0 mode is active [[br]]1: IO state is forced to OFF mode value when DS0 mode is active
  [19] CONF_GPMC_BE1N_SLEWCTRL rw — Select between Faster or Slower Slew rate [[br]]0 = fast [[br]]1 = slow
  [18] CONF_GPMC_BE1N_RXACTIVE rw — Input Enable Value for the PAD [[br]]0 = receiver disabled [[br]]1 = receiver enabled
  [17] CONF_GPMC_BE1N_PUTYPESEL rw — Pad Pullup / Pulldown Type Selection [[br]]0 = Pulldown selected [[br]]1 = Pullup selected
  [16] CONF_GPMC_BE1N_PUDEN rw — Pad Pullup / Pulldown Enable. [[br]]This is an active low signal [[br]]1 = Pullup / Pulldown disabled [[br]]0 = Pullup / Pulldown enabled
  [3:0] CONF_GPMC_BE1N_MMODE rw — Pad Functional Signal Mux Select
{0x87C+4i} CTRL_CONF_GPMC_CSN{i} (i=0..3)
  [30] CONF_GPMC_CSN{i}_WUEVT ro — Wakeup Event [[br]]0 = No event [[br]]1 = Event occurred
  [29] CONF_GPMC_CSN{i}_WUEN rw — Wakeup enable [[br]]0 = disable [[br]]1 = enable
  [28] CONF_GPMC_CSN{i}_DSPULLTYPESELECT rw — DS0 mode Pull-Up/Down selection [[br]]0 = Offmode Pull-Down selected [[br]]1 = Offmode Pull-Up selected
  [27] CONF_GPMC_CSN{i}_DSPULLUDEN rw — DS0 mode Pull-Up/Down enable. [[br]]This is an active low signal. [[br]]1 = Pullup / Pulldown disabled [[br]]0 = Pullup / Pulldown enabled
  [26] CONF_GPMC_CSN{i}_DS0OUTVALUE rw — DS0 mode output value [[br]]0 = Set value at 0 [[br]]1 = Set value at 1
  [25] CONF_GPMC_CSN{i}_DS0OUTEN rw — DS0 mode output enable This is an active low signal [[br]]0 = Output Enable [[br]]1 = Output Disable
  [24] CONF_GPMC_CSN{i}_DS0EN rw — DS0 mode override control [[br]]0: IO state keeps its previous state when DS0 mode is active [[br]]1: IO state is forced to OFF mode value when DS0 mode is active
  [19] CONF_GPMC_CSN{i}_SLEWCTRL rw — Select between Faster or Slower Slew rate [[br]]0 = fast [[br]]1 = slow
  [18] CONF_GPMC_CSN{i}_RXACTIVE rw — Input Enable Value for the PAD [[br]]0 = receiver disabled [[br]]1 = receiver enabled
  [17] CONF_GPMC_CSN{i}_PUTYPESEL rw — Pad Pullup / Pulldown Type Selection [[br]]0 = Pulldown selected [[br]]1 = Pullup selected
  [16] CONF_GPMC_CSN{i}_PUDEN rw — Pad Pullup / Pulldown Enable. [[br]]This is an active low signal [[br]]1 = Pullup / Pulldown disabled [[br]]0 = Pullup / Pulldown enabled
  [3:0] CONF_GPMC_CSN{i}_MMODE rw — Pad Functional Signal Mux Select
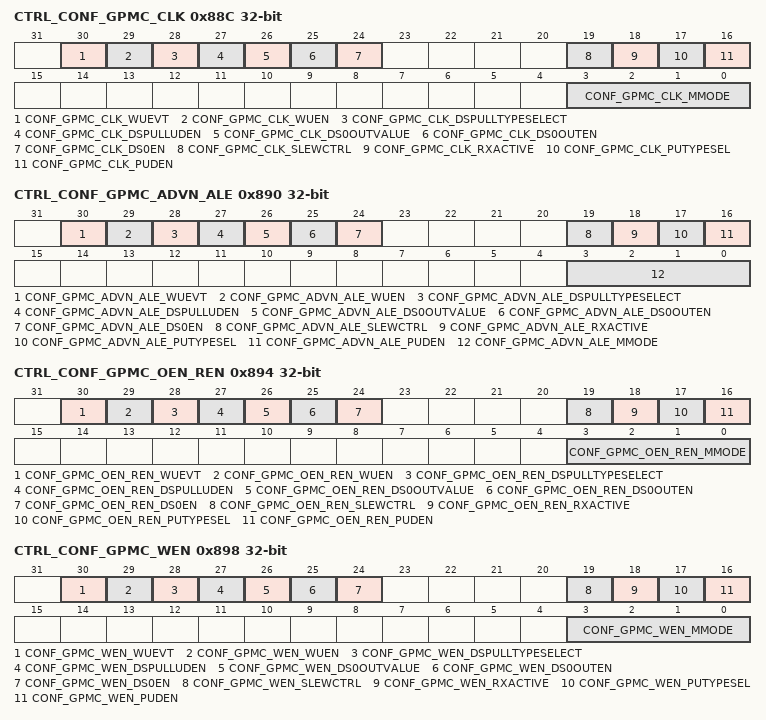
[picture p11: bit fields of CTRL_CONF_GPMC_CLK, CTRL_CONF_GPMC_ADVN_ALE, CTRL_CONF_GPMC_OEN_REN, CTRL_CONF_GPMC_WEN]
0x88C CTRL_CONF_GPMC_CLK
  [30] CONF_GPMC_CLK_WUEVT ro — Wakeup Event [[br]]0 = No event [[br]]1 = Event occurred
  [29] CONF_GPMC_CLK_WUEN rw — Wakeup enable [[br]]0 = disable [[br]]1 = enable
  [28] CONF_GPMC_CLK_DSPULLTYPESELECT rw — DS0 mode Pull-Up/Down selection [[br]]0 = Offmode Pull-Down selected [[br]]1 = Offmode Pull-Up selected
  [27] CONF_GPMC_CLK_DSPULLUDEN rw — DS0 mode Pull-Up/Down enable. [[br]]This is an active low signal. [[br]]1 = Pullup / Pulldown disabled [[br]]0 = Pullup / Pulldown enabled
  [26] CONF_GPMC_CLK_DS0OUTVALUE rw — DS0 mode output value [[br]]0 = Set value at 0 [[br]]1 = Set value at 1
  [25] CONF_GPMC_CLK_DS0OUTEN rw — DS0 mode output enable This is an active low signal [[br]]0 = Output Enable [[br]]1 = Output Disable
  [24] CONF_GPMC_CLK_DS0EN rw — DS0 mode override control [[br]]0: IO state keeps its previous state when DS0 mode is active [[br]]1: IO state is forced to OFF mode value when DS0 mode is active
  [19] CONF_GPMC_CLK_SLEWCTRL rw — Select between Faster or Slower Slew rate [[br]]0 = fast [[br]]1 = slow
  [18] CONF_GPMC_CLK_RXACTIVE rw — Input Enable Value for the PAD [[br]]0 = receiver disabled [[br]]1 = receiver enabled
  [17] CONF_GPMC_CLK_PUTYPESEL rw — Pad Pullup / Pulldown Type Selection [[br]]0 = Pulldown selected [[br]]1 = Pullup selected
  [16] CONF_GPMC_CLK_PUDEN rw — Pad Pullup / Pulldown Enable. [[br]]This is an active low signal [[br]]1 = Pullup / Pulldown disabled [[br]]0 = Pullup / Pulldown enabled
  [3:0] CONF_GPMC_CLK_MMODE rw — Pad Functional Signal Mux Select
0x890 CTRL_CONF_GPMC_ADVN_ALE
  [30] CONF_GPMC_ADVN_ALE_WUEVT ro — Wakeup Event [[br]]0 = No event [[br]]1 = Event occurred
  [29] CONF_GPMC_ADVN_ALE_WUEN rw — Wakeup enable [[br]]0 = disable [[br]]1 = enable
  [28] CONF_GPMC_ADVN_ALE_DSPULLTYPESELECT rw — DS0 mode Pull-Up/Down selection [[br]]0 = Offmode Pull-Down selected [[br]]1 = Offmode Pull-Up selected
  [27] CONF_GPMC_ADVN_ALE_DSPULLUDEN rw — DS0 mode Pull-Up/Down enable. [[br]]This is an active low signal. [[br]]1 = Pullup / Pulldown disabled [[br]]0 = Pullup / Pulldown enabled
  [26] CONF_GPMC_ADVN_ALE_DS0OUTVALUE rw — DS0 mode output value [[br]]0 = Set value at 0 [[br]]1 = Set value at 1
  [25] CONF_GPMC_ADVN_ALE_DS0OUTEN rw — DS0 mode output enable This is an active low signal [[br]]0 = Output Enable [[br]]1 = Output Disable
  [24] CONF_GPMC_ADVN_ALE_DS0EN rw — DS0 mode override control [[br]]0: IO state keeps its previous state when DS0 mode is active [[br]]1: IO state is forced to OFF mode value when DS0 mode is active
  [19] CONF_GPMC_ADVN_ALE_SLEWCTRL rw — Select between Faster or Slower Slew rate [[br]]0 = fast [[br]]1 = slow
  [18] CONF_GPMC_ADVN_ALE_RXACTIVE rw — Input Enable Value for the PAD [[br]]0 = receiver disabled [[br]]1 = receiver enabled
  [17] CONF_GPMC_ADVN_ALE_PUTYPESEL rw — Pad Pullup / Pulldown Type Selection [[br]]0 = Pulldown selected [[br]]1 = Pullup selected
  [16] CONF_GPMC_ADVN_ALE_PUDEN rw — Pad Pullup / Pulldown Enable. [[br]]This is an active low signal [[br]]1 = Pullup / Pulldown disabled [[br]]0 = Pullup / Pulldown enabled
  [3:0] CONF_GPMC_ADVN_ALE_MMODE rw — Pad Functional Signal Mux Select
0x894 CTRL_CONF_GPMC_OEN_REN
  [30] CONF_GPMC_OEN_REN_WUEVT ro — Wakeup Event [[br]]0 = No event [[br]]1 = Event occurred
  [29] CONF_GPMC_OEN_REN_WUEN rw — Wakeup enable [[br]]0 = disable [[br]]1 = enable
  [28] CONF_GPMC_OEN_REN_DSPULLTYPESELECT rw — DS0 mode Pull-Up/Down selection [[br]]0 = Offmode Pull-Down selected [[br]]1 = Offmode Pull-Up selected
  [27] CONF_GPMC_OEN_REN_DSPULLUDEN rw — DS0 mode Pull-Up/Down enable. [[br]]This is an active low signal. [[br]]1 = Pullup / Pulldown disabled [[br]]0 = Pullup / Pulldown enabled
  [26] CONF_GPMC_OEN_REN_DS0OUTVALUE rw — DS0 mode output value [[br]]0 = Set value at 0 [[br]]1 = Set value at 1
  [25] CONF_GPMC_OEN_REN_DS0OUTEN rw — DS0 mode output enable This is an active low signal [[br]]0 = Output Enable [[br]]1 = Output Disable
  [24] CONF_GPMC_OEN_REN_DS0EN rw — DS0 mode override control [[br]]0: IO state keeps its previous state when DS0 mode is active [[br]]1: IO state is forced to OFF mode value when DS0 mode is active
  [19] CONF_GPMC_OEN_REN_SLEWCTRL rw — Select between Faster or Slower Slew rate [[br]]0 = fast [[br]]1 = slow
  [18] CONF_GPMC_OEN_REN_RXACTIVE rw — Input Enable Value for the PAD [[br]]0 = receiver disabled [[br]]1 = receiver enabled
  [17] CONF_GPMC_OEN_REN_PUTYPESEL rw — Pad Pullup / Pulldown Type Selection [[br]]0 = Pulldown selected [[br]]1 = Pullup selected
  [16] CONF_GPMC_OEN_REN_PUDEN rw — Pad Pullup / Pulldown Enable. [[br]]This is an active low signal [[br]]1 = Pullup / Pulldown disabled [[br]]0 = Pullup / Pulldown enabled
  [3:0] CONF_GPMC_OEN_REN_MMODE rw — Pad Functional Signal Mux Select
0x898 CTRL_CONF_GPMC_WEN
  [30] CONF_GPMC_WEN_WUEVT ro — Wakeup Event [[br]]0 = No event [[br]]1 = Event occurred
  [29] CONF_GPMC_WEN_WUEN rw — Wakeup enable [[br]]0 = disable [[br]]1 = enable
  [28] CONF_GPMC_WEN_DSPULLTYPESELECT rw — DS0 mode Pull-Up/Down selection [[br]]0 = Offmode Pull-Down selected [[br]]1 = Offmode Pull-Up selected
  [27] CONF_GPMC_WEN_DSPULLUDEN rw — DS0 mode Pull-Up/Down enable. [[br]]This is an active low signal. [[br]]1 = Pullup / Pulldown disabled [[br]]0 = Pullup / Pulldown enabled
  [26] CONF_GPMC_WEN_DS0OUTVALUE rw — DS0 mode output value [[br]]0 = Set value at 0 [[br]]1 = Set value at 1
  [25] CONF_GPMC_WEN_DS0OUTEN rw — DS0 mode output enable This is an active low signal [[br]]0 = Output Enable [[br]]1 = Output Disable
  [24] CONF_GPMC_WEN_DS0EN rw — DS0 mode override control [[br]]0: IO state keeps its previous state when DS0 mode is active [[br]]1: IO state is forced to OFF mode value when DS0 mode is active
  [19] CONF_GPMC_WEN_SLEWCTRL rw — Select between Faster or Slower Slew rate [[br]]0 = fast [[br]]1 = slow
  [18] CONF_GPMC_WEN_RXACTIVE rw — Input Enable Value for the PAD [[br]]0 = receiver disabled [[br]]1 = receiver enabled
  [17] CONF_GPMC_WEN_PUTYPESEL rw — Pad Pullup / Pulldown Type Selection [[br]]0 = Pulldown selected [[br]]1 = Pullup selected
  [16] CONF_GPMC_WEN_PUDEN rw — Pad Pullup / Pulldown Enable. [[br]]This is an active low signal [[br]]1 = Pullup / Pulldown disabled [[br]]0 = Pullup / Pulldown enabled
  [3:0] CONF_GPMC_WEN_MMODE rw — Pad Functional Signal Mux Select
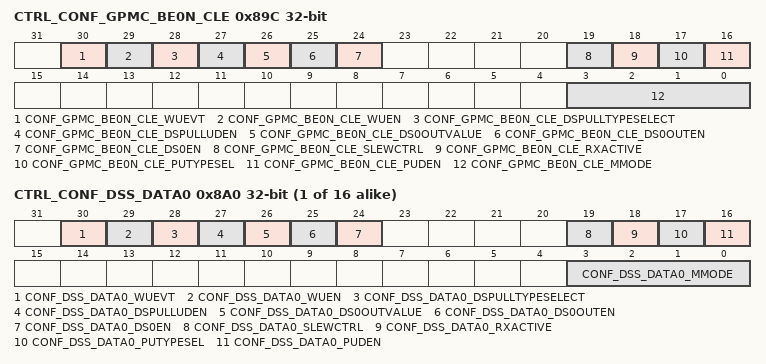
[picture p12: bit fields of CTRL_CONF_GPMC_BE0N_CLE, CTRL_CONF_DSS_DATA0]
0x89C CTRL_CONF_GPMC_BE0N_CLE
  [30] CONF_GPMC_BE0N_CLE_WUEVT ro — Wakeup Event [[br]]0 = No event [[br]]1 = Event occurred
  [29] CONF_GPMC_BE0N_CLE_WUEN rw — Wakeup enable [[br]]0 = disable [[br]]1 = enable
  [28] CONF_GPMC_BE0N_CLE_DSPULLTYPESELECT rw — DS0 mode Pull-Up/Down selection [[br]]0 = Offmode Pull-Down selected [[br]]1 = Offmode Pull-Up selected
  [27] CONF_GPMC_BE0N_CLE_DSPULLUDEN rw — DS0 mode Pull-Up/Down enable. [[br]]This is an active low signal. [[br]]1 = Pullup / Pulldown disabled [[br]]0 = Pullup / Pulldown enabled
  [26] CONF_GPMC_BE0N_CLE_DS0OUTVALUE rw — DS0 mode output value [[br]]0 = Set value at 0 [[br]]1 = Set value at 1
  [25] CONF_GPMC_BE0N_CLE_DS0OUTEN rw — DS0 mode output enable This is an active low signal [[br]]0 = Output Enable [[br]]1 = Output Disable
  [24] CONF_GPMC_BE0N_CLE_DS0EN rw — DS0 mode override control [[br]]0: IO state keeps its previous state when DS0 mode is active [[br]]1: IO state is forced to OFF mode value when DS0 mode is active
  [19] CONF_GPMC_BE0N_CLE_SLEWCTRL rw — Select between Faster or Slower Slew rate [[br]]0 = fast [[br]]1 = slow
  [18] CONF_GPMC_BE0N_CLE_RXACTIVE rw — Input Enable Value for the PAD [[br]]0 = receiver disabled [[br]]1 = receiver enabled
  [17] CONF_GPMC_BE0N_CLE_PUTYPESEL rw — Pad Pullup / Pulldown Type Selection [[br]]0 = Pulldown selected [[br]]1 = Pullup selected
  [16] CONF_GPMC_BE0N_CLE_PUDEN rw — Pad Pullup / Pulldown Enable. [[br]]This is an active low signal [[br]]1 = Pullup / Pulldown disabled [[br]]0 = Pullup / Pulldown enabled
  [3:0] CONF_GPMC_BE0N_CLE_MMODE rw — Pad Functional Signal Mux Select
{0x8A0+4i} CTRL_CONF_DSS_DATA{i} (i=0..15)
  [30] CONF_DSS_DATA{i}_WUEVT ro — Wakeup Event [[br]]0 = No event [[br]]1 = Event occurred
  [29] CONF_DSS_DATA{i}_WUEN rw — Wakeup enable [[br]]0 = disable [[br]]1 = enable
  [28] CONF_DSS_DATA{i}_DSPULLTYPESELECT rw — DS0 mode Pull-Up/Down selection [[br]]0 = Offmode Pull-Down selected [[br]]1 = Offmode Pull-Up selected
  [27] CONF_DSS_DATA{i}_DSPULLUDEN rw — DS0 mode Pull-Up/Down enable. [[br]]This is an active low signal. [[br]]1 = Pullup / Pulldown disabled [[br]]0 = Pullup / Pulldown enabled
  [26] CONF_DSS_DATA{i}_DS0OUTVALUE rw — DS0 mode output value [[br]]0 = Set value at 0 [[br]]1 = Set value at 1
  [25] CONF_DSS_DATA{i}_DS0OUTEN rw — DS0 mode output enable This is an active low signal [[br]]0 = Output Enable [[br]]1 = Output Disable
  [24] CONF_DSS_DATA{i}_DS0EN rw — DS0 mode override control [[br]]0: IO state keeps its previous state when DS0 mode is active [[br]]1: IO state is forced to OFF mode value when DS0 mode is active
  [19] CONF_DSS_DATA{i}_SLEWCTRL rw — Select between Faster or Slower Slew rate [[br]]0 = fast [[br]]1 = slow
  [18] CONF_DSS_DATA{i}_RXACTIVE rw — Input Enable Value for the PAD [[br]]0 = receiver disabled [[br]]1 = receiver enabled
  [17] CONF_DSS_DATA{i}_PUTYPESEL rw — Pad Pullup / Pulldown Type Selection [[br]]0 = Pulldown selected [[br]]1 = Pullup selected
  [16] CONF_DSS_DATA{i}_PUDEN rw — Pad Pullup / Pulldown Enable. [[br]]This is an active low signal [[br]]1 = Pullup / Pulldown disabled [[br]]0 = Pullup / Pulldown enabled
  [3:0] CONF_DSS_DATA{i}_MMODE rw — Pad Functional Signal Mux Select
